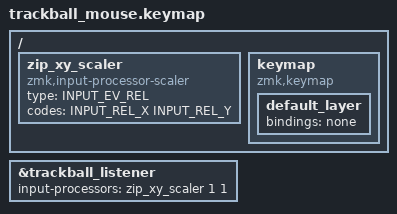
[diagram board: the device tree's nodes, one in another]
#include <behaviors.dtsi>
#include <dt-bindings/zmk/keys.h>
#include <dt-bindings/zmk/bt.h>
#include <dt-bindings/zmk/pointing.h>
#include <dt-bindings/input/input-event-codes.h>

/ {
    /* Scale trackball XY movement (numerator / denominator) */
    zip_xy_scaler: zip_xy_scaler {
        compatible = "zmk,input-processor-scaler";
        #input-processor-cells = <2>;
        type = <INPUT_EV_REL>;
        codes = <INPUT_REL_X INPUT_REL_Y>;
    };

    keymap {
        compatible = "zmk,keymap";
        default_layer {
            bindings = <&none>;
        };
    };
};

/* Apply XY scaler: multiplier 1, divisor 1 (1:1 ratio, adjust as needed) */
&trackball_listener {
    input-processors = <&zip_xy_scaler 1 1>;
};
